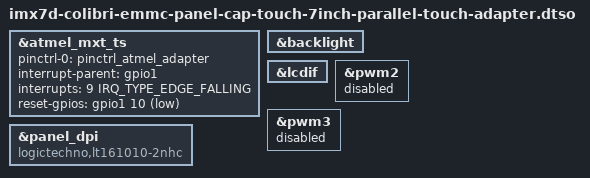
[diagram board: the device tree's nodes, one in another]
// SPDX-License-Identifier: GPL-2.0-or-later OR MIT
/*
 * Copyright (c) Toradex
 *
 * Toradex Capacitive Touch Display 7" Parallel connected through the 40-way
 * Unified Interface Display connector and Toradex Capacitive Touch Adapter.
 *
 * Toradex Capacitive Touch Adapter connection with the various carrier boards
 * is documented in the datasheet [1].
 *
 * https://developer.toradex.com/hardware/accessories/displays/capacitive-touch-display-7inch-parallel/
 * https://www.toradex.com/accessories/capacitive-touch-display-7-inch-parallel
 * https://docs.toradex.com/104497-7-inch-parallel-capacitive-touch-display-800x480-datasheet.pdf
 * https://developer.toradex.com/hardware/accessories/add-ons/capacitive-touch-adapter/
 * https://www.toradex.com/accessories/capacitive-touch-adapter
 * https://docs.toradex.com/104615-capacitive-touch-adapter-datasheet.pdf [1]
 */

/dts-v1/;
/plugin/;

#include <dt-bindings/gpio/gpio.h>
#include <dt-bindings/interrupt-controller/irq.h>

&atmel_mxt_ts {
	pinctrl-0 = <&pinctrl_atmel_adapter>;
	/* SODIMM 28 / TOUCH_INT# */
	interrupt-parent = <&gpio1>;
	interrupts = <9 IRQ_TYPE_EDGE_FALLING>;
	/* SODIMM 30 / TOUCH_RST# */
	reset-gpios = <&gpio1 10 GPIO_ACTIVE_LOW>;

	status = "okay";
};

&backlight {
	status = "okay";
};

&lcdif {
	status = "okay";
};

&panel_dpi {
	compatible = "logictechno,lt161010-2nhc";

	status = "okay";
};

/* Conflict with SODIMM 28 / TOUCH_INT# */
&pwm2 {
	status = "disabled";
};

/* Conflict with SODIMM 30 / TOUCH_RST# */
&pwm3 {
	status = "disabled";
};
